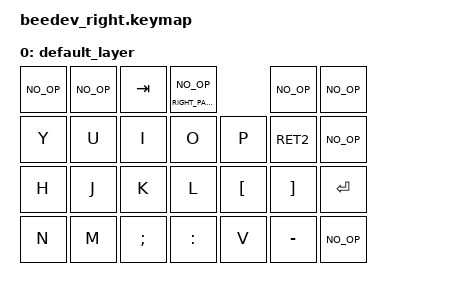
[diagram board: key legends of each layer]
#include <dt-bindings/zmk/keys.h>
#include <dt-bindings/zmk/bt.h>

#define RPAR = RAISE ;

keymap{
    compatible = "zmk,keymap";
    default_layer {
        bindings = <
            NO_OP   NO_OP   &kp TAB     &lt RIGHT_PARENTHESIS   NO_OP       NO_OP       NO_OP
            &kp Y   &kp U   &kp I       &kp O                   &kp P       &kp RET2    NO_OP
            &kp H   &kp J   &kp K       &kp L                   &kp LBKT    &kp RBKT    &kp RET
            &kp N   &kp M   &kp SEMI    &kp COLON               &kp V       &kp MINUS   NO_OP
        >;
    };
};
